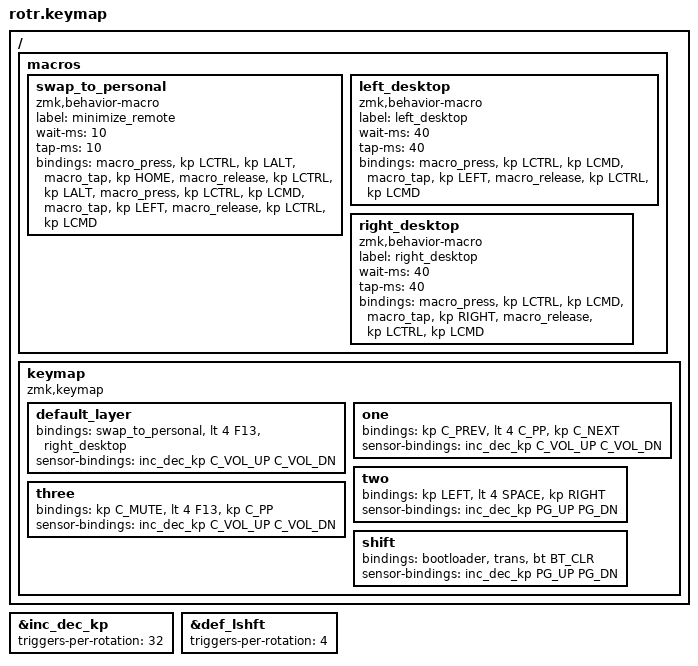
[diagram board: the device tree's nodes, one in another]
#include <behaviors.dtsi>
#include <dt-bindings/zmk/keys.h>
#include <dt-bindings/zmk/rgb.h>
#include <dt-bindings/zmk/bt.h>

&inc_dec_kp {
	triggers-per-rotation = <32>;
};
&def_lshft {
	triggers-per-rotation = <4>;
};

/ {
	macros {
		swap_to_personal: swap_to_personal {
		    label = "minimize_remote";
		    compatible = "zmk,behavior-macro";
		    #binding-cells = <0>;
		    wait-ms = <10>;
		    tap-ms = <10>;
		    bindings
			= <&macro_press &kp LCTRL &kp LALT>
			, <&macro_tap &kp HOME>
			, <&macro_release &kp LCTRL &kp LALT>
			, <&macro_press &kp LCTRL &kp LCMD>
			, <&macro_tap &kp LEFT>
			, <&macro_release &kp LCTRL &kp LCMD>
			;
		};
		left_desktop: left_desktop {
		    label = "left_desktop";
		    compatible = "zmk,behavior-macro";
		    #binding-cells = <0>;
		    wait-ms = <40>;
		    tap-ms = <40>;
		    bindings
			= <&macro_press &kp LCTRL &kp LCMD>
			, <&macro_tap &kp LEFT>
			, <&macro_release &kp LCTRL &kp LCMD>
			;
        	};
		right_desktop: right_desktop {
		    label = "right_desktop";
		    compatible = "zmk,behavior-macro";
		    #binding-cells = <0>;
		    wait-ms = <40>;
		    tap-ms = <40>;
		    bindings
			= <&macro_press &kp LCTRL &kp LCMD>
			, <&macro_tap &kp RIGHT>
			, <&macro_release &kp LCTRL &kp LCMD>
			;
        	};
    	};
	keymap {
		compatible = "zmk,keymap";

		default_layer {
			//LEFT DESKTOP | MINIMIZE REMOTE DESKTOP | RIGHT DESKTOP
			bindings = <&swap_to_personal &lt 4 F13 &right_desktop>;
			sensor-bindings = <&inc_dec_kp C_VOL_UP C_VOL_DN>;
		};
		one {
			//PREV | PLAY/PAUSE | NEXT
			bindings = <&kp C_PREV &lt 4 C_PP &kp C_NEXT>;
			sensor-bindings = <&inc_dec_kp C_VOL_UP C_VOL_DN>;
		};
		two {
			//PREV | PLAY/PAUSE | NEXT
			bindings = <&kp LEFT &lt 4 SPACE &kp RIGHT>;
			sensor-bindings = <&inc_dec_kp PG_UP PG_DN>;
		};
		three {
			//PREV | PLAY/PAUSE | NEXT
			bindings = <&kp C_MUTE &lt 4 F13 &kp C_PP>;
			sensor-bindings = <&inc_dec_kp C_VOL_UP C_VOL_DN>;
		};
		shift {
			//PREV | PLAY/PAUSE | NEXT
			bindings = <&bootloader &trans &bt BT_CLR>;
			//sensor-bindings = <&def_lshft>;
			sensor-bindings = <&inc_dec_kp PG_UP PG_DN>;
		};
	};
};
